AUTOSAR XML (schema 4-1-3)
standard types defined: boolean, sint8, uint16, uint32, uint8, boolean_CompuMethod, boolean_DataConstr, sint8_DataConstr, uint16_DataConstr, uint32_DataConstr, uint8_DataConstr, sint16
package /MICROSAR/Dem_swc/DataTypes
  5 x impl type:
    Dem_DebounceResetStatusType: compu {0=DEM_DEBOUNCE_STATUS_FREEZE, 1=DEM_DEBOUNCE_STATUS_RESET}, range raw 0..255, implementation-data-type=ImplementationDataTypes/uint8
    Dem_DTCFormatType: compu {0=DEM_DTC_FORMAT_OBD, 1=DEM_DTC_FORMAT_UDS, 2=DEM_DTC_FORMAT_J1939}, range raw 0..2, implementation-data-type=ImplementationDataTypes/uint8
    Dem_EventStatusType:
      compu {0=DEM_EVENT_STATUS_PASSED, 1=DEM_EVENT_STATUS_FAILED, 2=DEM_EVENT_STATUS_PREPASSED, 3=DEM_EVENT_STATUS_PREFAILED, 4=DEM_EVENT_STATUS_FDC_THRESHOLD_REACHED, 5=DEM_EVENT_STATUS_PASSED_CONDITIONS_NOT_FULFILLED, 6=DEM_EVENT_STATUS_FAILED_CONDITIONS_NOT_FULFILLED, 7=DEM_EVENT_STATUS_PREPASSED_CONDITIONS_NOT_FULFILLED, 8=DEM_EVENT_STATUS_PREFAILED_CONDITIONS_NOT_FULFILLED}
      range raw 0..255
      implementation-data-type=ImplementationDataTypes/uint8
    Dem_MaxDataValueType: category=ARRAY, sw-calibration-access=READ-ONLY
      element Dem_MaxDataValueTypeElement: array-size=40, array-size-semantics=FIXED-SIZE, implementation-data-type=ImplementationDataTypes/uint8
    Dem_UdsStatusByteType:
      compu {mask 1: 1=DEM_UDS_STATUS_TF (bit 0: TestFailed), mask 2: 2=DEM_UDS_STATUS_TFTOC (bit 1: TestFailedThisOperationCycle), mask 4: 4=DEM_UDS_STATUS_PDTC (bit 2: PendingDTC), mask 8: 8=DEM_UDS_STATUS_CDTC (bit 3: ConfirmedDTC), mask 16: 16=DEM_UDS_STATUS_TNCSLC (bit 4: TestNotCompletedSinceLastClear), mask 32: 32=DEM_UDS_STATUS_TFSLC (bit 5: TestFailedSinceLastClear), mask 64: 64=DEM_UDS_STATUS_TNCTOC (bit 6: TestNotCompletedThisOperationCycle), mask 128: 128=DEM_UDS_STATUS_WIR (bit 7: WarningIndicatorRequested)}
      range raw 0..255
      implementation-data-type=ImplementationDataTypes/uint8
package /MICROSAR/Dem_swc/Interfaces
  client server interface DiagnosticMonitor: is-service=true, service-kind=DIAGNOSTIC-EVENT-MANAGER
    11 x operation:
      GetDTCOfEvent: possible-error=[DEM_E_NO_DTC_AVAILABLE, DiagnosticMonitor/E_NOT_OK]
        arg DTCFormat: type=Dem_DTCFormatType, direction=IN, server-argument-impl-policy=USE-ARGUMENT-TYPE
        arg DTCOfEvent: type=uint32, direction=OUT, server-argument-impl-policy=USE-ARGUMENT-TYPE
      GetEventExtendedDataRecordEx: possible-error=[DEM_BUFFER_TOO_SMALL, DEM_NO_SUCH_ELEMENT, DiagnosticMonitor/E_NOT_OK]
        arg RecordNumber: type=ImplementationDataTypes/uint8, direction=IN, server-argument-impl-policy=USE-ARGUMENT-TYPE
        arg DestBuffer: type=Dem_MaxDataValueType, direction=OUT, server-argument-impl-policy=USE-ARGUMENT-TYPE
        arg BufSize: type=ImplementationDataTypes/uint16, direction=INOUT, server-argument-impl-policy=USE-ARGUMENT-TYPE
      GetEventFailed: possible-error=DiagnosticMonitor/E_NOT_OK
        arg EventFailed: type=ImplementationDataTypes/boolean, direction=OUT, server-argument-impl-policy=USE-ARGUMENT-TYPE
      GetEventFreezeFrameDataEx: possible-error=[DEM_BUFFER_TOO_SMALL, DEM_NO_SUCH_ELEMENT, DiagnosticMonitor/E_NOT_OK]
        4 x arg, all with server-argument-impl-policy=USE-ARGUMENT-TYPE:
          RecordNumber: type=ImplementationDataTypes/uint8, direction=IN
          DataId: type=ImplementationDataTypes/uint16, direction=IN
          DestBuffer: type=Dem_MaxDataValueType, direction=OUT
          BufSize: type=ImplementationDataTypes/uint16, direction=INOUT
      GetEventStatus: possible-error=DiagnosticMonitor/E_NOT_OK
        arg UDSStatusByte: type=Dem_UdsStatusByteType, direction=OUT, server-argument-impl-policy=USE-ARGUMENT-TYPE
      GetEventTested: possible-error=DiagnosticMonitor/E_NOT_OK
        arg EventTested: type=ImplementationDataTypes/boolean, direction=OUT, server-argument-impl-policy=USE-ARGUMENT-TYPE
      GetEventUdsStatus: possible-error=DiagnosticMonitor/E_NOT_OK
        arg UDSStatusByte: type=Dem_UdsStatusByteType, direction=OUT, server-argument-impl-policy=USE-ARGUMENT-TYPE
      GetFaultDetectionCounter: possible-error=[DEM_E_NO_FDC_AVAILABLE, DiagnosticMonitor/E_NOT_OK]
        arg FaultDetectionCounter: type=sint8, direction=OUT, server-argument-impl-policy=USE-ARGUMENT-TYPE
      ResetEventDebounceStatus: possible-error=DiagnosticMonitor/E_NOT_OK
        arg DebounceResetStatus: type=Dem_DebounceResetStatusType, direction=IN, server-argument-impl-policy=USE-ARGUMENT-TYPE
      ResetEventStatus: possible-error=DiagnosticMonitor/E_NOT_OK
      SetEventStatus: possible-error=DiagnosticMonitor/E_NOT_OK
        arg EventStatus: type=Dem_EventStatusType, direction=IN, server-argument-impl-policy=USE-ARGUMENT-TYPE
    5 x error:
      DEM_BUFFER_TOO_SMALL: error-code=21
      DEM_E_NO_DTC_AVAILABLE: error-code=10
      DEM_E_NO_FDC_AVAILABLE: error-code=14
      DEM_NO_SUCH_ELEMENT: error-code=48
      E_NOT_OK: error-code=1
package /UAES/ASW/ApplicationDataTypes
  7 x app type, all with sw-calibration-access=READ-WRITE:
    Appl_EvaprT_tTrfReSnsr_CUR: category=CURVE, sw-calprm-axis-set={sw-axis-index=1, category=COM_AXIS, sw-axis-individual={compu {phys=raw for raw -INF..INF; unit mV}, sw-max-axis-points=30, sw-min-axis-points=30, range phys 0..65535, raw 0..65535}}, compu {phys=raw*0.1-273.14 for raw -INF..INF; unit DegC}, range raw -32768..32767
    Appl_EvaprT_tTrfSnsr_CUR: category=CURVE, sw-calprm-axis-set={sw-axis-index=1, category=COM_AXIS, sw-axis-individual={compu {phys=raw for raw -INF..INF; unit mV}, sw-max-axis-points=30, sw-min-axis-points=30, range phys 0..65535, raw 0..65535}}, compu {phys=raw*0.1-273.14 for raw -INF..INF; unit DegC}, range raw -32768..32767
    Appl_EvaprT_tTrfSnsr_CUR{2..4}: category=CURVE, sw-calprm-axis-set={sw-axis-index=1, category=COM_AXIS, sw-axis-individual={compu {phys=raw for raw -INF..INF; unit mV}, sw-max-axis-points=30, sw-min-axis-points=30, range phys 0..65535, raw 0..65535}}, compu {phys=raw*0.1-273.14 for raw -INF..INF; unit DegC}, range raw -32768..32767
    T_q0p1_o273p14_DegC_s16: category=VALUE, compu {phys=raw*0.1-273.14 for raw -INF..INF; unit DegC}, range raw -32768..32767
    U_q1_mV_u16: category=VALUE, compu {phys=raw for raw -INF..INF; unit mV}, range phys 0..65535, raw 0..65535
package /UAES/ASW/CompuMethods
  compu method CM_boolean: 0=FALSE, 1=TRUE
package /UAES/ASW/DataConstrs
  range DC_boolean: raw 0..1
  range DC_sint16: raw -32768..32767
  range DC_uint16: phys 0..6553.5, raw 0..65535
package /UAES/ASW/DataTypeMappingSets
  data type mapping set DTMS_EvaprT_DD
    data-type-maps:
      application-data-type=Appl_EvaprT_tTrfReSnsr_CUR, implementation-data-type=EvaprT_tTrfReSnsr_CUR_Type
      application-data-type=Appl_EvaprT_tTrfSnsr_CUR, implementation-data-type=EvaprT_tTrfSnsr_CUR_Type
      application-data-type=Appl_EvaprT_tTrfSnsr_CUR{2..4}, implementation-data-type=EvaprT_tTrfSnsr_CUR{2..4}_Type
      application-data-type=T_q0p1_o273p14_DegC_s16, implementation-data-type=sint16
      application-data-type=U_q1_mV_u16, implementation-data-type=ImplementationDataTypes/uint16
package /UAES/ASW/ImplementationDataTypes
  9 x impl type:
    EvaprT_tTrfReSnsr_CUR_Type: category=STRUCTURE
      element N1: implementation-data-type=ImplementationDataTypes/uint16
      element BP1: implementation-data-type=rt_Array_U_q1_mV_u16_30
      element Table: implementation-data-type=rt_Array_T_q0p1_o273p14_DegC_s16_30
    EvaprT_tTrfSnsr_CUR_Type: category=STRUCTURE
      element N1: implementation-data-type=ImplementationDataTypes/uint16
      element BP1: implementation-data-type=rt_Array_U_q1_mV_u16_30
      element Table: implementation-data-type=rt_Array_T_q0p1_o273p14_DegC_s16_30
    EvaprT_tTrfSnsr_CUR2_Type: category=STRUCTURE
      element N1: implementation-data-type=ImplementationDataTypes/uint16
      element BP1: implementation-data-type=rt_Array_U_q1_mV_u16_30
      element Table: implementation-data-type=rt_Array_T_q0p1_o273p14_DegC_s16_30
    EvaprT_tTrfSnsr_CUR3_Type: category=STRUCTURE
      element N1: implementation-data-type=ImplementationDataTypes/uint16
      element BP1: implementation-data-type=rt_Array_U_q1_mV_u16_30
      element Table: implementation-data-type=rt_Array_T_q0p1_o273p14_DegC_s16_30
    EvaprT_tTrfSnsr_CUR4_Type: category=STRUCTURE
      element N1: implementation-data-type=ImplementationDataTypes/uint16
      element BP1: implementation-data-type=rt_Array_U_q1_mV_u16_30
      element Table: implementation-data-type=rt_Array_T_q0p1_o273p14_DegC_s16_30
    rt_Array_T_q0p1_o273p14_DegC_s16_30: category=ARRAY
      element rt_Array_T_q0p1_o273p14_DegC_s16_30: array-size=30, array-size-semantics=FIXED-SIZE, implementation-data-type=T_q0p1_o273p14_DegC_s16
    rt_Array_U_q1_mV_u16_30: category=ARRAY
      element rt_Array_U_q1_mV_u16_30: array-size=30, array-size-semantics=FIXED-SIZE, implementation-data-type=U_q1_mV_u16
    T_q0p1_o273p14_DegC_s16: category=VALUE, base-type=sint16, range raw -32768..32767
    U_q1_mV_u16: category=VALUE, base-type=BaseTypes/uint16, range phys 0..65535, raw 0..65535
package /UAES/ASW/ImplementationDataTypes/Ground
  13 x constant specification:
    EvaprT_numRawVoltFildPoint_C: value-spec=EvaprT_numRawVoltFildPoint_C:3
    EvaprT_numReRawVoltFildPoint_C: value-spec=EvaprT_numRawVoltFildPoint_C:16
    EvaprT_tDfl_C: value-spec=0.060000000000002274 DegC
    EvaprT_tReDfl_C: value-spec=0.060000000000002274 DegC
    EvaprT_tTrfReSnsr_CUR: value-spec=fields=[N:30, X:[279, 380, 446, 525, 619, 731, 866, 1026, 1213, 1430, 1675, 1728, 1781, 1836, 1891, 1948, 2006, 2064, 2123, 2183, 2243, 2305, 2367, 2429, 2492, 2556, 2870, 3183, 3484, 4235], Y:[3431, 3331, 3281, 3231, 3181, 3131, 3081, 3031, 2981, 2931, 2881, 2871, 2861, 2851, 2841, 2831, 2821, 2811, 2801, 2791, 2781, 2771, 2761, 2751, 2741, 2731, 2681, 2631, 2581, 2431]]
    EvaprT_tTrfSnsr_CUR: value-spec=fields=[N:30, X:[306, 417, 489, 573, 675, 795, 936, 1102, 1294, 1515, 1764, 1817, 1870, 1926, 1982, 2039, 2097, 2156, 2215, 2276, 2337, 2399, 2461, 2524, 2587, 2651, 2971, 3288, 3589, 4318], Y:[3431, 3331, 3281, 3231, 3181, 3131, 3081, 3031, 2981, 2931, 2881, 2871, 2861, 2851, 2841, 2831, 2821, 2811, 2801, 2791, 2781, 2771, 2761, 2751, 2741, 2731, 2681, 2631, 2581, 2431]]
    EvaprT_tTrfSnsr_CUR2: value-spec=fields=[N:30, X:[547, 743, 1008, 1360, 1804, 2333, 2446, 2561, 2676, 2793, 2909, 3025, 3083, 3140, 3197, 3254, 3310, 3366, 3420, 3471, 3528, 3581, 3632, 3683, 3734, 3783, 3831, 3878, 3969, 4353], Y:[3431, 3331, 3231, 3131, 3031, 2931, 2911, 2891, 2871, 2851, 2831, 2811, 2801, 2791, 2781, 2771, 2761, 2751, 2741, 2731, 2721, 2711, 2701, 2691, 2681, 2671, 2661, 2651, 2631, 2531]]
    EvaprT_tTrfSnsr_CUR3: value-spec=fields=[N:30, X:[740, 876, 1004, 1188, 1355, 1799, 2328, 2614, 2907, 3023, 3081, 3139, 3196, 3253, 3309, 3365, 3420, 3475, 3528, 3581, 3633, 3685, 3735, 3784, 3833, 3880, 3971, 4357, 4625, 4796], Y:[3331, 3281, 3231, 3181, 3131, 3031, 2931, 2871, 2831, 2811, 2801, 2791, 2781, 2771, 2761, 2751, 2741, 2731, 2721, 2711, 2701, 2691, 2681, 2671, 2661, 2651, 2631, 2531, 2431, 2331]]
    EvaprT_tTrfSnsr_CUR4: value-spec=fields=[N:30, X:[300, 409, 478, 562, 662, 782, 923, 1091, 1287, 1510, 1763, 1817, 1872, 1928, 1984, 2042, 2100, 2159, 2219, 2279, 2340, 2401, 2463, 2526, 2588, 2651, 2965, 3273, 3833, 4285], Y:[3431, 3331, 3281, 3231, 3181, 3131, 3081, 3031, 2981, 2931, 2881, 2871, 2861, 2851, 2841, 2831, 2821, 2811, 2801, 2791, 2781, 2771, 2761, 2751, 2741, 2731, 2681, 2631, 2581, 2431]]
    EvaprT_uRawMaxSRC_C: value-spec=4930 mV
    EvaprT_uRawMinSRC_C: value-spec=68 mV
    EvaprT_uRawReMaxSRC_C: value-spec=4930 mV
    EvaprT_uRawReMinSRC_C: value-spec=68 mV
package /UAES/ASW/PortInterfaces
  client server interface IoHwAb_IoSigAdc
    operation Adc_Get: possible-error=IoHwAb_IoSigAdc/E_NOT_OK
      arg id_u16: type=ImplementationDataTypes/uint16, direction=IN, server-argument-impl-policy=USE-ARGUMENT-TYPE
      arg val_s16: type=sint16, direction=OUT, server-argument-impl-policy=USE-ARGUMENT-TYPE
    operation AdcFac_Get: possible-error=IoHwAb_IoSigAdc/E_NOT_OK
      arg id_u16: type=ImplementationDataTypes/uint16, direction=IN, server-argument-impl-policy=USE-ARGUMENT-TYPE
      arg val_s16: type=sint16, direction=OUT, server-argument-impl-policy=USE-ARGUMENT-TYPE
    operation AdcVRMBatt_Get: possible-error=IoHwAb_IoSigAdc/E_NOT_OK
      arg id_u16: type=ImplementationDataTypes/uint16, direction=IN, server-argument-impl-policy=USE-ARGUMENT-TYPE
      arg val_u8: type=ImplementationDataTypes/uint8, direction=OUT, server-argument-impl-policy=USE-ARGUMENT-TYPE
    error E_NOT_OK: error-code=1
  9 x sender receiver interface:
    BattU_bVoltEnbPinDiag: invalidation-policy{data-element=BattU_bVoltEnbPinDiag/Val, handle-invalid=DONT-INVALIDATE}
      data Val: sw-calibration-access=READ-ONLY, type=ImplementationDataTypes/boolean
    EvaprT_t: invalidation-policy{data-element=EvaprT_t/Val, handle-invalid=DONT-INVALIDATE}
      data Val: sw-calibration-access=READ-ONLY, type=T_q0p1_o273p14_DegC_s16
    EvaprT_tRe: invalidation-policy{data-element=EvaprT_tRe/Val, handle-invalid=DONT-INVALIDATE}
      data Val: sw-calibration-access=READ-ONLY, type=T_q0p1_o273p14_DegC_s16
    EvaprT_uRaw: invalidation-policy{data-element=EvaprT_uRaw/Val, handle-invalid=DONT-INVALIDATE}
      data Val: sw-calibration-access=READ-ONLY, type=U_q1_mV_u16
    EvaprT_uRawRe: invalidation-policy{data-element=EvaprT_uRawRe/Val, handle-invalid=DONT-INVALIDATE}
      data Val: sw-calibration-access=READ-ONLY, type=U_q1_mV_u16
    gPRM_u8AirConditionBoxSpecCfg: invalidation-policy{data-element=gPRM_u8AirConditionBoxSpecCfg/Val, handle-invalid=DONT-INVALIDATE}
      data Val: sw-calibration-access=READ-ONLY, type=ImplementationDataTypes/uint8
    gPRM_u8ReAirConditionBoxSpecCfg: invalidation-policy{data-element=gPRM_u8ReAirConditionBoxSpecCfg/Val, handle-invalid=DONT-INVALIDATE}
      data Val: sw-calibration-access=READ-ONLY, type=ImplementationDataTypes/uint8
    gPRM_u8VehicleTypeCfg: invalidation-policy{data-element=gPRM_u8VehicleTypeCfg/Val, handle-invalid=DONT-INVALIDATE}
      data Val: sw-calibration-access=READ-ONLY, range raw 0..255, type=ImplementationDataTypes/uint8
    VehCoorn_stPwrMod: invalidation-policy{data-element=VehCoorn_stPwrMod/Val, handle-invalid=DONT-INVALIDATE}
      data Val: sw-calibration-access=READ-ONLY, type=ImplementationDataTypes/uint8
package /UAES/ASW/SwAddrMethods
  sw addr method CALDATA
package /UAES/ASW/SwComponentTypes
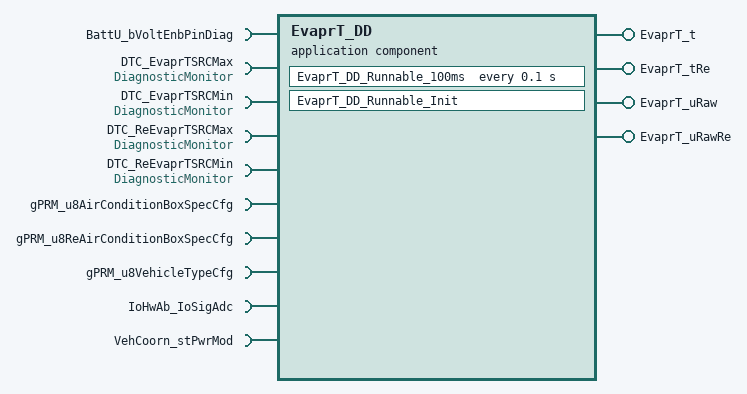
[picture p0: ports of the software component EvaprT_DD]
  application sw component type EvaprT_DD
    4 x provide port:
      EvaprT_t: nonqueued-sender-com-spec{data-element=EvaprT_t/Val, init-value=0}, provided-interface=EvaprT_t
      EvaprT_tRe: nonqueued-sender-com-spec{data-element=EvaprT_tRe/Val, init-value=0}, provided-interface=EvaprT_tRe
      EvaprT_uRaw: nonqueued-sender-com-spec{data-element=EvaprT_uRaw/Val, init-value=0}, provided-interface=EvaprT_uRaw
      EvaprT_uRawRe: nonqueued-sender-com-spec{data-element=EvaprT_uRawRe/Val, init-value=0}, provided-interface=EvaprT_uRawRe
    10 x require port:
      BattU_bVoltEnbPinDiag: nonqueued-receiver-com-spec{data-element=BattU_bVoltEnbPinDiag/Val, filter=data-filter-type=ALWAYS, init-value=0}, required-interface=BattU_bVoltEnbPinDiag
      DTC_EvaprTSRCMax: required-interface=DiagnosticMonitor
        required-com-specs:
          GetDTCOfEvent
          GetEventExtendedDataRecordEx
          GetEventFailed
          GetEventFreezeFrameDataEx
          GetEventStatus
          GetEventTested
          GetEventUdsStatus
          GetFaultDetectionCounter
          ResetEventDebounceStatus
          ResetEventStatus
          SetEventStatus
      DTC_EvaprTSRCMin: required-interface=DiagnosticMonitor
        required-com-specs:
          GetDTCOfEvent
          GetEventExtendedDataRecordEx
          GetEventFailed
          GetEventFreezeFrameDataEx
          GetEventStatus
          GetEventTested
          GetEventUdsStatus
          GetFaultDetectionCounter
          ResetEventDebounceStatus
          ResetEventStatus
          SetEventStatus
      DTC_ReEvaprTSRCMax: required-interface=DiagnosticMonitor
        required-com-specs:
          GetDTCOfEvent
          GetEventExtendedDataRecordEx
          GetEventFailed
          GetEventFreezeFrameDataEx
          GetEventStatus
          GetEventTested
          GetEventUdsStatus
          GetFaultDetectionCounter
          ResetEventDebounceStatus
          ResetEventStatus
          SetEventStatus
      DTC_ReEvaprTSRCMin: required-interface=DiagnosticMonitor
        required-com-specs:
          GetDTCOfEvent
          GetEventExtendedDataRecordEx
          GetEventFailed
          GetEventFreezeFrameDataEx
          GetEventStatus
          GetEventTested
          GetEventUdsStatus
          GetFaultDetectionCounter
          ResetEventDebounceStatus
          ResetEventStatus
          SetEventStatus
      gPRM_u8AirConditionBoxSpecCfg: nonqueued-receiver-com-spec{data-element=gPRM_u8AirConditionBoxSpecCfg/Val, filter=data-filter-type=ALWAYS, init-value=0}, required-interface=gPRM_u8AirConditionBoxSpecCfg
      gPRM_u8ReAirConditionBoxSpecCfg: nonqueued-receiver-com-spec{data-element=gPRM_u8ReAirConditionBoxSpecCfg/Val, filter=data-filter-type=ALWAYS, init-value=0}, required-interface=gPRM_u8ReAirConditionBoxSpecCfg
      gPRM_u8VehicleTypeCfg: nonqueued-receiver-com-spec{data-element=gPRM_u8VehicleTypeCfg/Val, filter=data-filter-type=ALWAYS, init-value=0}, required-interface=gPRM_u8VehicleTypeCfg
      IoHwAb_IoSigAdc: required-com-specs=[Adc_Get, AdcFac_Get, AdcVRMBatt_Get], required-interface=IoHwAb_IoSigAdc
      VehCoorn_stPwrMod: nonqueued-receiver-com-spec{data-element=VehCoorn_stPwrMod/Val, filter=data-filter-type=ALWAYS, init-value=0}, required-interface=VehCoorn_stPwrMod
    behavior EvaprT_DD_InternalBehavior: data-type-mapping=DTMS_EvaprT_DD
      timing event TMT_EvaprT_DD_Runnable_100ms: start-on-event=EvaprT_DD_Runnable_100ms, period=0.1
      init event EvaprT_DD_InitEvent: start-on-event=EvaprT_DD_Runnable_Init
      runnable EvaprT_DD_Runnable_100ms
        data-receive-point-by-arguments:
          5 x access:
            REC_BattU_bVoltEnbPinDiag_Val: accessed-variable=BattU_bVoltEnbPinDiag.Val
            REC_gPRM_u8AirConditionBoxSpecCfg_Val: accessed-variable=gPRM_u8AirConditionBoxSpecCfg.Val
            REC_gPRM_u8ReAirConditionBoxSpecCfg_Val: accessed-variable=gPRM_u8ReAirConditionBoxSpecCfg.Val
            REC_gPRM_u8VehicleTypeCfg_Val: accessed-variable=gPRM_u8VehicleTypeCfg.Val
            REC_VehCoorn_stPwrMod_Val: accessed-variable=VehCoorn_stPwrMod.Val
        data-send-points:
          4 x access:
            SEND_EvaprT_t_Val: accessed-variable=EvaprT_t.Val
            SEND_EvaprT_tRe_Val: accessed-variable=EvaprT_tRe.Val
            SEND_EvaprT_uRaw_Val: accessed-variable=EvaprT_uRaw.Val
            SEND_EvaprT_uRawRe_Val: accessed-variable=EvaprT_uRawRe.Val
        13 x parameter access:
          PA_EvaprT_numRawVoltFildPoint_C: accessed-parameter=EvaprT_numRawVoltFildPoint_C
          PA_EvaprT_numReRawVoltFildPoint_C: accessed-parameter=EvaprT_numReRawVoltFildPoint_C
          PA_EvaprT_tDfl_C: accessed-parameter=EvaprT_tDfl_C
          PA_EvaprT_tReDfl_C: accessed-parameter=EvaprT_tReDfl_C
          PA_EvaprT_tTrfReSnsr_CUR: accessed-parameter=EvaprT_tTrfReSnsr_CUR
          PA_EvaprT_tTrfSnsr_CUR: accessed-parameter=EvaprT_tTrfSnsr_CUR
          PA_EvaprT_tTrfSnsr_CUR{2..4}: accessed-parameter=EvaprT_tTrfSnsr_CUR{2..4}
          PA_EvaprT_uRawMaxSRC_C: accessed-parameter=EvaprT_uRawMaxSRC_C
          PA_EvaprT_uRawMinSRC_C: accessed-parameter=EvaprT_uRawMinSRC_C
          PA_EvaprT_uRawReMaxSRC_C: accessed-parameter=EvaprT_uRawReMaxSRC_C
          PA_EvaprT_uRawReMinSRC_C: accessed-parameter=EvaprT_uRawReMinSRC_C
        17 x sync call:
          SC_DTC_EvaprTSRCMax_GetEventFailed: operation=DTC_EvaprTSRCMax.GetEventFailed, timeout=1E-06
          SC_DTC_EvaprTSRCMax_GetEventTested: operation=DTC_EvaprTSRCMax.GetEventTested, timeout=1E-06
          SC_DTC_EvaprTSRCMax_ResetEventDebounceStatus: operation=DTC_EvaprTSRCMax.ResetEventDebounceStatus, timeout=1E-06
          SC_DTC_EvaprTSRCMax_SetEventStatus: operation=DTC_EvaprTSRCMax.SetEventStatus, timeout=1E-06
          SC_DTC_EvaprTSRCMin_GetEventFailed: operation=DTC_EvaprTSRCMin.GetEventFailed, timeout=1E-06
          SC_DTC_EvaprTSRCMin_GetEventTested: operation=DTC_EvaprTSRCMin.GetEventTested, timeout=1E-06
          SC_DTC_EvaprTSRCMin_ResetEventDebounceStatus: operation=DTC_EvaprTSRCMin.ResetEventDebounceStatus, timeout=1E-06
          SC_DTC_EvaprTSRCMin_SetEventStatus: operation=DTC_EvaprTSRCMin.SetEventStatus, timeout=1E-06
          SC_DTC_ReEvaprTSRCMax_GetEventFailed: operation=DTC_ReEvaprTSRCMax.GetEventFailed, timeout=1E-06
          SC_DTC_ReEvaprTSRCMax_GetEventTested: operation=DTC_ReEvaprTSRCMax.GetEventTested, timeout=1E-06
          SC_DTC_ReEvaprTSRCMax_ResetEventDebounceStatus: operation=DTC_ReEvaprTSRCMax.ResetEventDebounceStatus, timeout=1E-06
          SC_DTC_ReEvaprTSRCMax_SetEventStatus: operation=DTC_ReEvaprTSRCMax.SetEventStatus, timeout=1E-06
          SC_DTC_ReEvaprTSRCMin_GetEventFailed: operation=DTC_ReEvaprTSRCMin.GetEventFailed, timeout=1E-06
          SC_DTC_ReEvaprTSRCMin_GetEventTested: operation=DTC_ReEvaprTSRCMin.GetEventTested, timeout=1E-06
          SC_DTC_ReEvaprTSRCMin_ResetEventDebounceStatus: operation=DTC_ReEvaprTSRCMin.ResetEventDebounceStatus, timeout=1E-06
          SC_DTC_ReEvaprTSRCMin_SetEventStatus: operation=DTC_ReEvaprTSRCMin.SetEventStatus, timeout=1E-06
          SC_IoHwAb_IoSigAdc_AdcFac_Get: operation=IoHwAb_IoSigAdc.AdcFac_Get, timeout=0
      runnable EvaprT_DD_Runnable_Init
        data-receive-point-by-arguments:
          5 x access:
            REC_BattU_bVoltEnbPinDiag_Val: accessed-variable=BattU_bVoltEnbPinDiag.Val
            REC_gPRM_u8AirConditionBoxSpecCfg_Val: accessed-variable=gPRM_u8AirConditionBoxSpecCfg.Val
            REC_gPRM_u8ReAirConditionBoxSpecCfg_Val: accessed-variable=gPRM_u8ReAirConditionBoxSpecCfg.Val
            REC_gPRM_u8VehicleTypeCfg_Val: accessed-variable=gPRM_u8VehicleTypeCfg.Val
            REC_VehCoorn_stPwrMod_Val: accessed-variable=VehCoorn_stPwrMod.Val
        data-send-points:
          4 x access:
            SEND_EvaprT_t_Val: accessed-variable=EvaprT_t.Val
            SEND_EvaprT_tRe_Val: accessed-variable=EvaprT_tRe.Val
            SEND_EvaprT_uRaw_Val: accessed-variable=EvaprT_uRaw.Val
            SEND_EvaprT_uRawRe_Val: accessed-variable=EvaprT_uRawRe.Val
        13 x parameter access:
          PA_EvaprT_numRawVoltFildPoint_C: accessed-parameter=EvaprT_numRawVoltFildPoint_C
          PA_EvaprT_numReRawVoltFildPoint_C: accessed-parameter=EvaprT_numReRawVoltFildPoint_C
          PA_EvaprT_tDfl_C: accessed-parameter=EvaprT_tDfl_C
          PA_EvaprT_tReDfl_C: accessed-parameter=EvaprT_tReDfl_C
          PA_EvaprT_tTrfReSnsr_CUR: accessed-parameter=EvaprT_tTrfReSnsr_CUR
          PA_EvaprT_tTrfSnsr_CUR: accessed-parameter=EvaprT_tTrfSnsr_CUR
          PA_EvaprT_tTrfSnsr_CUR{2..4}: accessed-parameter=EvaprT_tTrfSnsr_CUR{2..4}
          PA_EvaprT_uRawMaxSRC_C: accessed-parameter=EvaprT_uRawMaxSRC_C
          PA_EvaprT_uRawMinSRC_C: accessed-parameter=EvaprT_uRawMinSRC_C
          PA_EvaprT_uRawReMaxSRC_C: accessed-parameter=EvaprT_uRawReMaxSRC_C
          PA_EvaprT_uRawReMinSRC_C: accessed-parameter=EvaprT_uRawReMinSRC_C
        sync call SC_IoHwAb_IoSigAdc_AdcFac_Get: operation=IoHwAb_IoSigAdc.AdcFac_Get, timeout=0
      shared-parameters:
        13 x parameter data prototype, all with sw-addr-method=CALDATA, sw-calibration-access=READ-WRITE:
          EvaprT_numRawVoltFildPoint_C: type=ImplementationDataTypes/uint8, init-value=constant-reference={short-label=EvaprT_numRawVoltFildPoint_C, constant=EvaprT_numRawVoltFildPoint_C}
          EvaprT_numReRawVoltFildPoint_C: type=ImplementationDataTypes/uint8, init-value=constant-reference={short-label=EvaprT_numRawVoltFildPoint_C, constant=EvaprT_numReRawVoltFildPoint_C}
          EvaprT_tDfl_C: type=T_q0p1_o273p14_DegC_s16, init-value=constant-reference={short-label=EvaprT_tDfl_C, constant=EvaprT_tDfl_C}
          EvaprT_tReDfl_C: type=T_q0p1_o273p14_DegC_s16, init-value=constant-reference={short-label=EvaprT_tDfl_C, constant=EvaprT_tReDfl_C}
          EvaprT_tTrfReSnsr_CUR: type=Appl_EvaprT_tTrfReSnsr_CUR, init-value=constant-reference={short-label=EvaprT_tTrfSnsr_CUR, constant=EvaprT_tTrfReSnsr_CUR}
          EvaprT_tTrfSnsr_CUR: type=Appl_EvaprT_tTrfSnsr_CUR, init-value=constant-reference={short-label=EvaprT_tTrfSnsr_CUR, constant=EvaprT_tTrfSnsr_CUR}
          EvaprT_tTrfSnsr_CUR2: type=Appl_EvaprT_tTrfSnsr_CUR2, init-value=constant-reference={short-label=EvaprT_tTrfSnsr_CUR2, constant=EvaprT_tTrfSnsr_CUR2}
          EvaprT_tTrfSnsr_CUR3: type=Appl_EvaprT_tTrfSnsr_CUR3, init-value=constant-reference={short-label=EvaprT_tTrfSnsr_CUR3, constant=EvaprT_tTrfSnsr_CUR3}
          EvaprT_tTrfSnsr_CUR4: type=Appl_EvaprT_tTrfSnsr_CUR4, init-value=constant-reference={short-label=EvaprT_tTrfSnsr_CUR3, constant=EvaprT_tTrfSnsr_CUR4}
          EvaprT_uRawMaxSRC_C: type=U_q1_mV_u16, init-value=constant-reference={short-label=EvaprT_uRawMaxSRC_C, constant=EvaprT_uRawMaxSRC_C}
          EvaprT_uRawMinSRC_C: type=U_q1_mV_u16, init-value=constant-reference={short-label=EvaprT_uRawMinSRC_C, constant=EvaprT_uRawMinSRC_C}
          EvaprT_uRawReMaxSRC_C: type=U_q1_mV_u16, init-value=constant-reference={short-label=EvaprT_uRawMaxSRC_C, constant=EvaprT_uRawReMaxSRC_C}
          EvaprT_uRawReMinSRC_C: type=U_q1_mV_u16, init-value=constant-reference={short-label=EvaprT_uRawMinSRC_C, constant=EvaprT_uRawReMinSRC_C}
  swc implementation EvaprT_DD_Implementation: behavior=EvaprT_DD_InternalBehavior
    code-descriptors:
      code Default: artifact-descriptors=autosar-engineering-object={short-label=Default, category=SWSRC}
package /UAES/ASW/Units
  unit DegC: display-name=DegC, factor-si-to-unit=1, offset-si-to-unit=0
  unit mV: display-name=mV, factor-si-to-unit=1, offset-si-to-unit=0
  unit NoUnit: factor-si-to-unit=1, offset-si-to-unit=0
